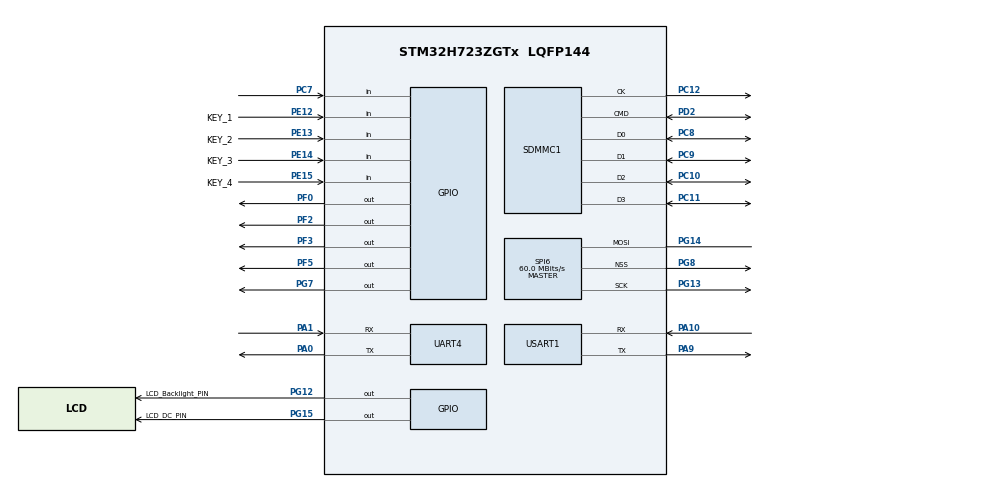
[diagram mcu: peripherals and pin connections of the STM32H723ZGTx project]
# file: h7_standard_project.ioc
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CORTEX_M7.default_mode_Activation=1
Dma.Request0=USART1_RX
Dma.USART1_RX.0.Direction=DMA_PERIPH_TO_MEMORY
Dma.USART1_RX.0.EventEnable=DISABLE
Dma.USART1_RX.0.FIFOMode=DMA_FIFOMODE_DISABLE
Dma.USART1_RX.0.Instance=DMA1_Stream0
Dma.USART1_RX.0.MemDataAlignment=DMA_MDATAALIGN_BYTE
Dma.USART1_RX.0.MemInc=DMA_MINC_ENABLE
Dma.USART1_RX.0.Mode=DMA_NORMAL
Dma.USART1_RX.0.PeriphDataAlignment=DMA_PDATAALIGN_BYTE
Dma.USART1_RX.0.PeriphInc=DMA_PINC_DISABLE
Dma.USART1_RX.0.Polarity=HAL_DMAMUX_REQ_GEN_RISING
Dma.USART1_RX.0.Priority=DMA_PRIORITY_LOW
Dma.USART1_RX.0.RequestNumber=1
Dma.USART1_RX.0.SignalID=NONE
Dma.USART1_RX.0.SyncEnable=DISABLE
Dma.USART1_RX.0.SyncPolarity=HAL_DMAMUX_SYNC_NO_EVENT
Dma.USART1_RX.0.SyncRequestNumber=1
Dma.USART1_RX.0.SyncSignalID=NONE
FATFS.BSP.number=1
FATFS._USE_LFN=2
FATFS0.BSP.STBoard=false
FATFS0.BSP.api=Unknown
FATFS0.BSP.instance=PC7
FATFS0.BSP.ip=GPIO
FATFS0.BSP.mode=Input
FATFS0.BSP.name=Detect_SDIO
FATFS0.BSP.solution=PC7
FREERTOS.Tasks01=StartTask,24,1024,StartDefaultTask,Default,NULL,Dynamic,NULL,NULL
FREERTOS.configTOTAL_HEAP_SIZE=40960
Mcu.Family=STM32H7
Mcu.Name=STM32H723ZGTx
Mcu.Package=LQFP144
NVIC.DMA1_Stream0_IRQn=true\:5\:0\:false\:false\:true\:true\:false\:true\:true
NVIC.PriorityGroup=NVIC_PRIORITYGROUP_4
NVIC.SDMMC1_IRQn=true\:5\:0\:true\:false\:true\:true\:true\:true\:true
NVIC.TIM6_DAC_IRQn=true\:15\:0\:false\:false\:true\:false\:false\:true\:true
NVIC.TimeBase=TIM6_DAC_IRQn
NVIC.TimeBaseIP=TIM6
NVIC.UART4_IRQn=true\:5\:0\:false\:false\:true\:true\:true\:true\:true
NVIC.USART1_IRQn=true\:5\:0\:false\:false\:true\:true\:true\:true\:true
PA0.Mode=Asynchronous
PA0.Signal=UART4_TX
PA1.Mode=Asynchronous
PA1.Signal=UART4_RX
PA10.Mode=Asynchronous
PA10.Signal=USART1_RX
PA9.Mode=Asynchronous
PA9.Signal=USART1_TX
PC10.GPIO_PuPd=GPIO_PULLUP
PC10.Mode=SD_4_bits_Wide_bus
PC10.Signal=SDMMC1_D2
PC11.GPIO_PuPd=GPIO_PULLUP
PC11.Mode=SD_4_bits_Wide_bus
PC11.Signal=SDMMC1_D3
PC12.GPIO_PuPd=GPIO_PULLUP
PC12.Mode=SD_4_bits_Wide_bus
PC12.Signal=SDMMC1_CK
PC7.Signal=GPIO_Input
PC8.GPIO_PuPd=GPIO_PULLUP
PC8.Mode=SD_4_bits_Wide_bus
PC8.Signal=SDMMC1_D0
PC9.GPIO_PuPd=GPIO_PULLUP
PC9.Mode=SD_4_bits_Wide_bus
PC9.Signal=SDMMC1_D1
PD2.GPIO_PuPd=GPIO_PULLUP
PD2.Mode=SD_4_bits_Wide_bus
PD2.Signal=SDMMC1_CMD
PE12.GPIO_Label=KEY_1
PE12.GPIO_PuPd=GPIO_PULLUP
PE12.Signal=GPIO_Input
PE13.GPIO_Label=KEY_2
PE13.GPIO_PuPd=GPIO_PULLUP
PE13.Signal=GPIO_Input
PE14.GPIO_Label=KEY_3
PE14.GPIO_PuPd=GPIO_PULLUP
PE14.Signal=GPIO_Input
PE15.GPIO_Label=KEY_4
PE15.GPIO_PuPd=GPIO_PULLUP
PE15.Signal=GPIO_Input
PF0.PinState=GPIO_PIN_RESET
PF0.Signal=GPIO_Output
PF2.PinState=GPIO_PIN_RESET
PF2.Signal=GPIO_Output
PF3.PinState=GPIO_PIN_RESET
PF3.Signal=GPIO_Output
PF5.PinState=GPIO_PIN_RESET
PF5.Signal=GPIO_Output
PG12.GPIO_Label=LCD_Backlight_PIN
PG12.GPIO_PuPd=GPIO_PULLDOWN
PG12.Signal=GPIO_Output
PG13.GPIO_Speed=GPIO_SPEED_FREQ_VERY_HIGH
PG13.Mode=Simplex_Bidirectional_Master
PG13.Signal=SPI6_SCK
PG14.GPIO_Speed=GPIO_SPEED_FREQ_VERY_HIGH
PG14.Mode=Simplex_Bidirectional_Master
PG14.Signal=SPI6_MOSI
PG15.GPIO_Label=LCD_DC_PIN
PG15.Signal=GPIO_Output
PG7.PinState=GPIO_PIN_SET
PG7.Signal=GPIO_Output
PG8.GPIO_Speed=GPIO_SPEED_FREQ_VERY_HIGH
PG8.Mode=NSS_Signal_Hard_Output
PG8.Signal=SPI6_NSS
PH0-OSC_IN.Mode=HSE-External-Oscillator
PH0-OSC_IN.Signal=RCC_OSC_IN
PH1-OSC_OUT.Mode=HSE-External-Oscillator
PH1-OSC_OUT.Signal=RCC_OSC_OUT
ProjectManager.HeapSize=0x1000
ProjectManager.StackSize=0x2000
ProjectManager.TargetToolchain=MDK-ARM V5.32
RCC.ADCFreq_Value=50390625
RCC.APB1Freq_Value=120000000
RCC.APB2Freq_Value=120000000
RCC.APB3Freq_Value=120000000
RCC.APB4Freq_Value=120000000
RCC.CortexFreq_Value=240000000
RCC.D1PPRE=RCC_APB3_DIV2
RCC.D2PPRE1=RCC_APB1_DIV2
RCC.D2PPRE2=RCC_APB2_DIV2
RCC.D3PPRE=RCC_APB4_DIV2
RCC.DIVM1=5
RCC.DIVN1=48
RCC.DIVP1=1
RCC.HCLKFreq_Value=240000000
RCC.PLL2FRACN=0
RCC.PLL3FRACN=0
RCC.PLLFRACN=0
RCC.PLLSourceVirtual=RCC_PLLSOURCE_HSE
RCC.SYSCLKFreq_VALUE=240000000
RCC.SYSCLKSource=RCC_SYSCLKSOURCE_PLLCLK
RCC.USBFreq_Value=120000000
SDMMC1.ClockDiv=0
SDMMC1.TransceiverPresent=SDMMC_TRANSCEIVER_NOT_PRESENT
SPI6.CalculateBaudRate=60.0 MBits/s
SPI6.DataSize=SPI_DATASIZE_8BIT
SPI6.Direction=SPI_DIRECTION_1LINE
SPI6.FifoThreshold=SPI_FIFO_THRESHOLD_02DATA
SPI6.Mode=SPI_MODE_MASTER
SPI6.NSSPMode=SPI_NSS_PULSE_DISABLE
SPI6.VirtualNSS=VM_NSSHARD
SPI6.VirtualType=VM_MASTER
USART1.VirtualMode-Asynchronous=VM_ASYNC
VP_FATFS_VS_SDIO.Mode=SDIO
VP_FREERTOS_VS_CMSIS_V2.Mode=CMSIS_V2
VP_MEMORYMAP_VS_MEMORYMAP.Mode=CurAppReg
VP_SYS_VS_tim6.Mode=TIM6
board=custom

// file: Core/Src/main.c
/* USER CODE BEGIN Header */
/**
  ******************************************************************************
  * @file           : main.c
  * @brief          : Main program body
  ******************************************************************************
  * @attention
  *
  * Copyright (c) 2026 STMicroelectronics.
  * All rights reserved.
  *
  * This software is licensed under terms that can be found in the LICENSE file
  * in the root directory of this software component.
  * If no LICENSE file comes with this software, it is provided AS-IS.
  *
  ******************************************************************************
  */
/* USER CODE END Header */
#include "main.h"
#include "cmsis_os.h"
#include "dma.h"
#include "fatfs.h"
#include "memorymap.h"
#include "sdmmc.h"
#include "spi.h"
#include "usart.h"
#include "gpio.h"

void SystemClock_Config(void);
static void MPU_Config(void);
void MX_FREERTOS_Init(void);

int main(void)
{

  /* USER CODE BEGIN 1 */
	SCB_EnableICache();		// ICache
//	SCB_EnableDCache();		// DCache

  /* USER CODE END 1 */

  /* MPU Configuration--------------------------------------------------------*/
  MPU_Config();

  /* MCU Configuration--------------------------------------------------------*/

  /* Reset of all peripherals, Initializes the Flash interface and the Systick. */
  HAL_Init();

  /* Configure the system clock */
  SystemClock_Config();

  /* Initialize all configured peripherals */
  MX_GPIO_Init();
  MX_DMA_Init();
  MX_USART1_UART_Init();
  MX_SPI6_Init();
  MX_UART4_Init();
  MX_SDMMC1_SD_Init();
  MX_FATFS_Init();

  /* Init scheduler */
  osKernelInitialize();

  /* Call init function for freertos objects (in cmsis_os2.c) */
  MX_FREERTOS_Init();

  /* Start scheduler */
  osKernelStart();

  /* We should never get here as control is now taken by the scheduler */

  /* Infinite loop */
  while (1)
  {

  }
}

void SystemClock_Config(void)
{
  RCC_OscInitTypeDef RCC_OscInitStruct = {0};
  RCC_ClkInitTypeDef RCC_ClkInitStruct = {0};

  /** Supply configuration update enable
  */
  HAL_PWREx_ConfigSupply(PWR_LDO_SUPPLY);

  /** Configure the main internal regulator output voltage
  */
  __HAL_PWR_VOLTAGESCALING_CONFIG(PWR_REGULATOR_VOLTAGE_SCALE0);

  while(!__HAL_PWR_GET_FLAG(PWR_FLAG_VOSRDY)) {}

  /** Initializes the RCC Oscillators according to the specified parameters
  * in the RCC_OscInitTypeDef structure.
  */
  RCC_OscInitStruct.OscillatorType = RCC_OSCILLATORTYPE_HSE;
  RCC_OscInitStruct.HSEState = RCC_HSE_ON;
  RCC_OscInitStruct.PLL.PLLState = RCC_PLL_ON;
  RCC_OscInitStruct.PLL.PLLSource = RCC_PLLSOURCE_HSE;
  RCC_OscInitStruct.PLL.PLLM = 5;
  RCC_OscInitStruct.PLL.PLLN = 48;
  RCC_OscInitStruct.PLL.PLLP = 1;
  RCC_OscInitStruct.PLL.PLLQ = 2;
  RCC_OscInitStruct.PLL.PLLR = 2;
  RCC_OscInitStruct.PLL.PLLRGE = RCC_PLL1VCIRANGE_2;
  RCC_OscInitStruct.PLL.PLLVCOSEL = RCC_PLL1VCOWIDE;
  RCC_OscInitStruct.PLL.PLLFRACN = 0;
  if (HAL_RCC_OscConfig(&RCC_OscInitStruct) != HAL_OK)
  {
    Error_Handler();
  }

  /** Initializes the CPU, AHB and APB buses clocks
  */
  RCC_ClkInitStruct.ClockType = RCC_CLOCKTYPE_HCLK|RCC_CLOCKTYPE_SYSCLK
                              |RCC_CLOCKTYPE_PCLK1|RCC_CLOCKTYPE_PCLK2
                              |RCC_CLOCKTYPE_D3PCLK1|RCC_CLOCKTYPE_D1PCLK1;
  RCC_ClkInitStruct.SYSCLKSource = RCC_SYSCLKSOURCE_PLLCLK;
  RCC_ClkInitStruct.SYSCLKDivider = RCC_SYSCLK_DIV1;
  RCC_ClkInitStruct.AHBCLKDivider = RCC_HCLK_DIV1;
  RCC_ClkInitStruct.APB3CLKDivider = RCC_APB3_DIV2;
  RCC_ClkInitStruct.APB1CLKDivider = RCC_APB1_DIV2;
  RCC_ClkInitStruct.APB2CLKDivider = RCC_APB2_DIV2;
  RCC_ClkInitStruct.APB4CLKDivider = RCC_APB4_DIV2;

  if (HAL_RCC_ClockConfig(&RCC_ClkInitStruct, FLASH_LATENCY_3) != HAL_OK)
  {
    Error_Handler();
  }
}

 /* MPU Configuration */

void MPU_Config(void)
{
  MPU_Region_InitTypeDef MPU_InitStruct = {0};

  /* Disables the MPU */
  HAL_MPU_Disable();

  /** Initializes and configures the Region and the memory to be protected
  */
  MPU_InitStruct.Enable = MPU_REGION_ENABLE;
  MPU_InitStruct.Number = MPU_REGION_NUMBER0;
  MPU_InitStruct.BaseAddress = 0x0;
  MPU_InitStruct.Size = MPU_REGION_SIZE_4GB;
  MPU_InitStruct.SubRegionDisable = 0x87;
  MPU_InitStruct.TypeExtField = MPU_TEX_LEVEL0;
  MPU_InitStruct.AccessPermission = MPU_REGION_NO_ACCESS;
  MPU_InitStruct.DisableExec = MPU_INSTRUCTION_ACCESS_DISABLE;
  MPU_InitStruct.IsShareable = MPU_ACCESS_SHAREABLE;
  MPU_InitStruct.IsCacheable = MPU_ACCESS_NOT_CACHEABLE;
  MPU_InitStruct.IsBufferable = MPU_ACCESS_NOT_BUFFERABLE;

  HAL_MPU_ConfigRegion(&MPU_InitStruct);
  /* Enables the MPU */
  HAL_MPU_Enable(MPU_PRIVILEGED_DEFAULT);

}

void HAL_TIM_PeriodElapsedCallback(TIM_HandleTypeDef *htim)
{
  if (htim->Instance == TIM6)
  {
    HAL_IncTick();
  }
}

void Error_Handler(void)
{
  __disable_irq();
  while (1)
  {
  }
}

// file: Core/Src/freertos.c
/* USER CODE BEGIN Header */
/**
  ******************************************************************************
  * File Name          : freertos.c
  * Description        : Code for freertos applications
  ******************************************************************************
  * @attention
  *
  * Copyright (c) 2026 STMicroelectronics.
  * All rights reserved.
  *
  * This software is licensed under terms that can be found in the LICENSE file
  * in the root directory of this software component.
  * If no LICENSE file comes with this software, it is provided AS-IS.
  *
  ******************************************************************************
  */
/* USER CODE END Header */

#include "FreeRTOS.h"
#include "task.h"
#include "main.h"
#include "cmsis_os.h"

/* USER CODE BEGIN Includes */

#include "usart.h"
#include "logger.h"

//static const char* TAG = "freertos";

extern void StartTask_Entry(void);

/* USER CODE END Includes */

/* Definitions for StartTask */
osThreadId_t StartTaskHandle;
const osThreadAttr_t StartTask_attributes = {
  .name = "StartTask",
  .stack_size = 1024 * 4,
  .priority = (osPriority_t) osPriorityNormal,
};

void StartDefaultTask(void *argument);

void MX_FREERTOS_Init(void); /* (MISRA C 2004 rule 8.1) */

void MX_FREERTOS_Init(void) {

  /* Create the thread(s) */
  /* creation of StartTask */
  StartTaskHandle = osThreadNew(StartDefaultTask, NULL, &StartTask_attributes);

}

void StartDefaultTask(void *argument)
{
  /* USER CODE BEGIN StartDefaultTask */
  /* Infinite loop */

	StartTask_Entry();

  for(;;)
  {

  }
  /* USER CODE END StartDefaultTask */
}
